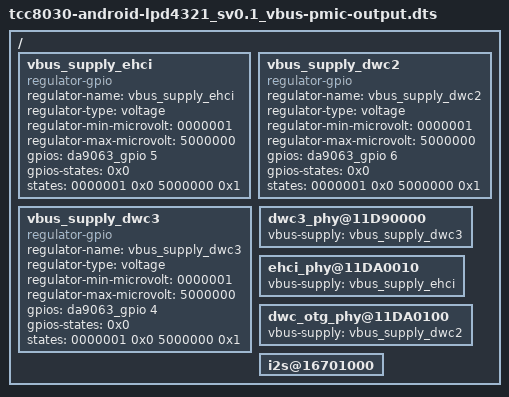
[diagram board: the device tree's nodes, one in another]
// SPDX-License-Identifier: (GPL-2.0-or-later OR MIT)
/*
 * Copyright (C) Telechips Inc.
 */

#include "tcc8030-android-lpd4321_sv0.1.dts"

/ {
	vbus_supply_ehci: vbus_supply_ehci {
		compatible = "regulator-gpio";
		regulator-name = "vbus_supply_ehci";
		regulator-type = "voltage";
		regulator-min-microvolt = <0000001>;
		regulator-max-microvolt = <5000000>;
		gpios = <&da9063_gpio 5 0x0>;
		gpios-states = <0x0>;
		states = <0000001 0x0 5000000 0x1>;
	};

	vbus_supply_dwc2: vbus_supply_dwc2 {
		compatible = "regulator-gpio";
		regulator-name = "vbus_supply_dwc2";
		regulator-type = "voltage";
		regulator-min-microvolt = <0000001>;
		regulator-max-microvolt = <5000000>;
		gpios = <&da9063_gpio 6 0x0>;
		gpios-states = <0x0>;
		states = <0000001 0x0 5000000 0x1>;
	};

	vbus_supply_dwc3: vbus_supply_dwc3 {
		compatible = "regulator-gpio";
		regulator-name = "vbus_supply_dwc3";
		regulator-type = "voltage";
		regulator-min-microvolt = <0000001>;
		regulator-max-microvolt = <5000000>;
		gpios = <&da9063_gpio 4 0x0>;
		gpios-states = <0x0>;
		states = <0000001 0x0 5000000 0x1>;
	};

	/* USB 3.0 DRD */
	dwc3_phy@11D90000 {
		vbus-supply = <&vbus_supply_dwc3>;
	};

	/* USB 2.0 HOST */
	ehci_phy@11DA0010 {
		vbus-supply = <&vbus_supply_ehci>;
	};

	/* USB 2.0 DRD */
	dwc_otg_phy@11DA0100 {
		vbus-supply = <&vbus_supply_dwc2>;
	};

	i2s@16701000 {
		status = "okay";
	};
};
